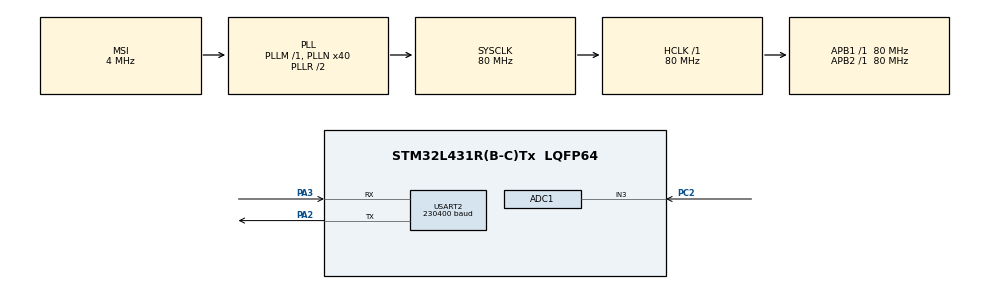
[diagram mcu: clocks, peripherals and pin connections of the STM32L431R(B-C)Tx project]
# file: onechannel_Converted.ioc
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ADC1.Channel-0\#ChannelRegularConversion=ADC_CHANNEL_3
ADC1.ContinuousConvMode=ENABLE
ADC1.NbrOfConversion=1
ADC1.NbrOfConversionFlag=1
ADC1.OffsetNumber-0\#ChannelRegularConversion=ADC_OFFSET_NONE
ADC1.Rank-0\#ChannelRegularConversion=1
ADC1.SamplingTime-0\#ChannelRegularConversion=ADC_SAMPLETIME_2CYCLES_5
ADC1.master=1
Mcu.Family=STM32L4
Mcu.Name=STM32L431R(B-C)Tx
Mcu.Package=LQFP64
Mcu.UserConstants=ADC_ConvertedValue,0
NVIC.ADC1_IRQn=true\:2\:0\:true\:false\:true\:true\:true\:true
NVIC.PriorityGroup=NVIC_PRIORITYGROUP_4
NVIC.USART2_IRQn=true\:0\:0\:false\:false\:true\:true\:true\:true
PA13\ (JTMS-SWDIO).Mode=Serial_Wire
PA13\ (JTMS-SWDIO).Signal=SYS_JTMS-SWDIO
PA14\ (JTCK-SWCLK).Mode=Serial_Wire
PA14\ (JTCK-SWCLK).Signal=SYS_JTCK-SWCLK
PA2.Mode=Asynchronous
PA2.Signal=USART2_TX
PA3.Mode=Asynchronous
PA3.Signal=USART2_RX
PC14-OSC32_IN\ (PC14).Mode=LSE-External-Oscillator
PC14-OSC32_IN\ (PC14).Signal=RCC_OSC32_IN
PC15-OSC32_OUT\ (PC15).Mode=LSE-External-Oscillator
PC15-OSC32_OUT\ (PC15).Signal=RCC_OSC32_OUT
PC2.Signal=ADCx_IN3
PH0-OSC_IN\ (PH0).Mode=HSE-External-Oscillator
PH0-OSC_IN\ (PH0).Signal=RCC_OSC_IN
PH1-OSC_OUT\ (PH1).Mode=HSE-External-Oscillator
PH1-OSC_OUT\ (PH1).Signal=RCC_OSC_OUT
ProjectManager.HeapSize=0x200
ProjectManager.StackSize=0x400
ProjectManager.TargetToolchain=MDK-ARM V5.32
RCC.ADCFreq_Value=32000000
RCC.AHBFreq_Value=80000000
RCC.APB1Freq_Value=80000000
RCC.APB1TimFreq_Value=80000000
RCC.APB2Freq_Value=80000000
RCC.APB2TimFreq_Value=80000000
RCC.CortexFreq_Value=80000000
RCC.HCLKFreq_Value=80000000
RCC.HSE_VALUE=8000000
RCC.HSI48_VALUE=48000000
RCC.HSI_VALUE=16000000
RCC.LSE_Drive_CapabilityArg=+LSE_Drive_Capability
RCC.MSIAutoCalibration=DISABLED
RCC.MSI_VALUE=4000000
RCC.PLLN=40
RCC.PLLSAI1N=16
RCC.SYSCLKFreq_VALUE=80000000
RCC.SYSCLKSource=RCC_SYSCLKSOURCE_PLLCLK
RCC.VCOOutputFreq_Value=160000000
SH.ADCx_IN3.0=ADC1_IN3,IN3-Single-Ended
USART2.BaudRate=230400
USART2.VirtualMode-Asynchronous=VM_ASYNC
board=custom

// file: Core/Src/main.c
/* USER CODE BEGIN Header */
/**
  ******************************************************************************
  * @file           : main.c
  * @brief          : Main program body
  ******************************************************************************
  * @attention
  *
  * Copyright (c) 2023 STMicroelectronics.
  * All rights reserved.
  *
  * This software is licensed under terms that can be found in the LICENSE file
  * in the root directory of this software component.
  * If no LICENSE file comes with this software, it is provided AS-IS.
  *
  ******************************************************************************
  */
/* USER CODE END Header */
#include "main.h"
#include "stdio.h"

ADC_HandleTypeDef hadc1;

UART_HandleTypeDef huart2;

__IO uint32_t ADC_ConvertedValue = 0;

void SystemClock_Config(void);
static void MX_GPIO_Init(void);
static void MX_ADC1_Init(void);
static void MX_USART2_UART_Init(void);

int main(void)
{
  /* USER CODE BEGIN 1 */
	float ADC_Vol;
  /* USER CODE END 1 */

  /* MCU Configuration--------------------------------------------------------*/

  /* Reset of all peripherals, Initializes the Flash interface and the Systick. */
  HAL_Init();

  /* Configure the system clock */
  SystemClock_Config();

  /* Initialize all configured peripherals */
  MX_GPIO_Init();
  MX_ADC1_Init();
  MX_USART2_UART_Init();
		//HAL_ADC_Start(&hadc1);
  /* Infinite loop */
  while (1)
  {
				ADC_Vol =(float) ADC_ConvertedValue/4096*(float)3.3; // 读取转换的AD值
        printf("\r\n The current AD value = 0x%04X \r\n", ADC_ConvertedValue);
        printf("\r\n The current AD value = %f V \r\n",ADC_Vol);
				HAL_Delay(5000);
  }
}

void SystemClock_Config(void)
{
  RCC_OscInitTypeDef RCC_OscInitStruct = {0};
  RCC_ClkInitTypeDef RCC_ClkInitStruct = {0};

  /** Configure the main internal regulator output voltage
  */
  if (HAL_PWREx_ControlVoltageScaling(PWR_REGULATOR_VOLTAGE_SCALE1) != HAL_OK)
  {
    Error_Handler();
  }

  /** Initializes the RCC Oscillators according to the specified parameters
  * in the RCC_OscInitTypeDef structure.
  */
  RCC_OscInitStruct.OscillatorType = RCC_OSCILLATORTYPE_MSI;
  RCC_OscInitStruct.MSIState = RCC_MSI_ON;
  RCC_OscInitStruct.MSICalibrationValue = 0;
  RCC_OscInitStruct.MSIClockRange = RCC_MSIRANGE_6;
  RCC_OscInitStruct.PLL.PLLState = RCC_PLL_ON;
  RCC_OscInitStruct.PLL.PLLSource = RCC_PLLSOURCE_MSI;
  RCC_OscInitStruct.PLL.PLLM = 1;
  RCC_OscInitStruct.PLL.PLLN = 40;
  RCC_OscInitStruct.PLL.PLLP = RCC_PLLP_DIV7;
  RCC_OscInitStruct.PLL.PLLQ = RCC_PLLQ_DIV2;
  RCC_OscInitStruct.PLL.PLLR = RCC_PLLR_DIV2;
  if (HAL_RCC_OscConfig(&RCC_OscInitStruct) != HAL_OK)
  {
    Error_Handler();
  }

  /** Initializes the CPU, AHB and APB buses clocks
  */
  RCC_ClkInitStruct.ClockType = RCC_CLOCKTYPE_HCLK|RCC_CLOCKTYPE_SYSCLK
                              |RCC_CLOCKTYPE_PCLK1|RCC_CLOCKTYPE_PCLK2;
  RCC_ClkInitStruct.SYSCLKSource = RCC_SYSCLKSOURCE_PLLCLK;
  RCC_ClkInitStruct.AHBCLKDivider = RCC_SYSCLK_DIV1;
  RCC_ClkInitStruct.APB1CLKDivider = RCC_HCLK_DIV1;
  RCC_ClkInitStruct.APB2CLKDivider = RCC_HCLK_DIV1;

  if (HAL_RCC_ClockConfig(&RCC_ClkInitStruct, FLASH_LATENCY_4) != HAL_OK)
  {
    Error_Handler();
  }
}

static void MX_ADC1_Init(void)
{

  ADC_ChannelConfTypeDef sConfig = {0};

  /** Common config
  */
  hadc1.Instance = ADC1;
  hadc1.Init.ClockPrescaler = ADC_CLOCK_ASYNC_DIV1;
  hadc1.Init.Resolution = ADC_RESOLUTION_12B;
  hadc1.Init.DataAlign = ADC_DATAALIGN_RIGHT;
  hadc1.Init.ScanConvMode = ADC_SCAN_DISABLE;
  hadc1.Init.EOCSelection = ADC_EOC_SINGLE_CONV;
  hadc1.Init.LowPowerAutoWait = DISABLE;
  hadc1.Init.ContinuousConvMode = ENABLE;
  hadc1.Init.NbrOfConversion = 1;
  hadc1.Init.DiscontinuousConvMode = DISABLE;
  hadc1.Init.ExternalTrigConv = ADC_SOFTWARE_START;
  hadc1.Init.ExternalTrigConvEdge = ADC_EXTERNALTRIGCONVEDGE_NONE;
  hadc1.Init.DMAContinuousRequests = DISABLE;
  hadc1.Init.Overrun = ADC_OVR_DATA_PRESERVED;
  hadc1.Init.OversamplingMode = DISABLE;
  if (HAL_ADC_Init(&hadc1) != HAL_OK)
  {
    Error_Handler();
  }

  /** Configure Regular Channel
  */
  sConfig.Channel = ADC_CHANNEL_3;
  sConfig.Rank = ADC_REGULAR_RANK_1;
  sConfig.SamplingTime = ADC_SAMPLETIME_640CYCLES_5;
  sConfig.SingleDiff = ADC_SINGLE_ENDED;
  sConfig.OffsetNumber = ADC_OFFSET_NONE;
  sConfig.Offset = 0;
  if (HAL_ADC_ConfigChannel(&hadc1, &sConfig) != HAL_OK)
  {
    Error_Handler();
  }
  /* USER CODE BEGIN ADC1_Init 2 */
		HAL_ADC_Start_IT(&hadc1);

  /* USER CODE END ADC1_Init 2 */

}

static void MX_USART2_UART_Init(void)
{

  huart2.Instance = USART2;
  huart2.Init.BaudRate = 230400;
  huart2.Init.WordLength = UART_WORDLENGTH_8B;
  huart2.Init.StopBits = UART_STOPBITS_1;
  huart2.Init.Parity = UART_PARITY_NONE;
  huart2.Init.Mode = UART_MODE_TX_RX;
  huart2.Init.HwFlowCtl = UART_HWCONTROL_NONE;
  huart2.Init.OverSampling = UART_OVERSAMPLING_16;
  huart2.Init.OneBitSampling = UART_ONE_BIT_SAMPLE_DISABLE;
  huart2.AdvancedInit.AdvFeatureInit = UART_ADVFEATURE_NO_INIT;
  if (HAL_UART_Init(&huart2) != HAL_OK)
  {
    Error_Handler();
  }

}

static void MX_GPIO_Init(void)
{

  /* GPIO Ports Clock Enable */
  __HAL_RCC_GPIOC_CLK_ENABLE();
  __HAL_RCC_GPIOH_CLK_ENABLE();
  __HAL_RCC_GPIOA_CLK_ENABLE();

}

/* USER CODE BEGIN 4 */

/*****************  发送字符串 **********************/
void Usart_SendString(uint8_t *str)
{
	unsigned int k=0;
  do
  {
      HAL_UART_Transmit(&huart2,(uint8_t *)(str + k) ,1,1000);
      k++;
  } while(*(str + k)!='\0');

}
//重定向c库函数printf到串口DEBUG_USART，重定向后可使用printf函数
int fputc(int ch, FILE *f)
{
	/* 发送一个字节数据到串口DEBUG_USART */
	HAL_UART_Transmit(&huart2, (uint8_t *)&ch, 1, 1000);

	return (ch);
}

//重定向c库函数scanf到串口DEBUG_USART，重写向后可使用scanf、getchar等函数
int fgetc(FILE *f)
{
	int ch;
	HAL_UART_Receive(&huart2, (uint8_t *)&ch, 1, 1000);
	return (ch);
}

void HAL_ADC_ConvCpltCallback(ADC_HandleTypeDef * adchandle)
{
	ADC_ConvertedValue = HAL_ADC_GetValue(adchandle);
}
/* USER CODE END 4 */

void Error_Handler(void)
{
  __disable_irq();
  while (1)
  {
  }
}
